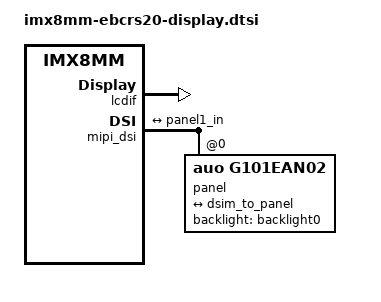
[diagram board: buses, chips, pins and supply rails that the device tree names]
// SPDX-License-Identifier: (GPL-2.0+ OR MIT)
/*
 * Copyright 2025 NXP
 */

#include "imx8mm-nxp-display.dtsi"


&lcdif {
	status = "okay";
};

&mipi_dsi {
	status = "okay";

	port@1 {
		reg = <1>;
		dsim_to_panel: endpoint {
			remote-endpoint = <&panel1_in>;
		};
	};

	panel@0 {
		compatible = "auo,g101ean02";
		reg = <0>;
		dsi-lanes = <4>;
		backlight = <&backlight0>;
		status = "okay";

		panel-init-sequence = [
			29 00 06 3C 01 05 00 03	00
			29 00 06 14 01 03 00 00	00
			29 00 06 64 01 05 00 00	00
			29 00 06 68 01 05 00 00	00
			29 00 06 6C 01 05 00 00	00
			29 00 06 70 01 05 00 00	00
			29 00 06 34 01 1F 00 00	00
			29 00 06 10 02 1F 00 00	00
			29 00 06 04 01 01 00 00	00
			29 00 06 04 02 01 00 00	00
			29 00 06 50 04 20 01 F0	03
			29 00 06 54 04 0A 00 0A	00
			29 00 06 58 04 00 05 8C	00
			29 00 06 5C 04 04 00 04	00
			29 00 06 60 04 20 03 0F	00
			29 00 06 64 04 01 00 00	00
			29 01 06 A0 04 06 80 44	00
			29 00 06 A0 04 06 80 04	00
			29 00 06 04 05 04 00 00	00
			29 00 06 80 04 00 01 02	03
			29 00 06 84 04 04 07 05	08
			29 00 06 88 04 09 0A 0E	0F
			29 00 06 8C 04 0B 0C 0D	10
			29 00 06 90 04 16 17 11	12
			29 00 06 94 04 13 14 15	1B
			29 14 06 98 04 18 19 1A	06
			29 78 06 9C 04 31 00 00	00
		];
		panel-on-sequence = [
			05 78 01 11
			05 78 01 29
		];
		panel-off-sequence = [
			05 05 01 28
			05 78 01 10
		];

		port {
			panel1_in: endpoint {
				remote-endpoint = <&dsim_to_panel>;
			};
		};
	};
};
